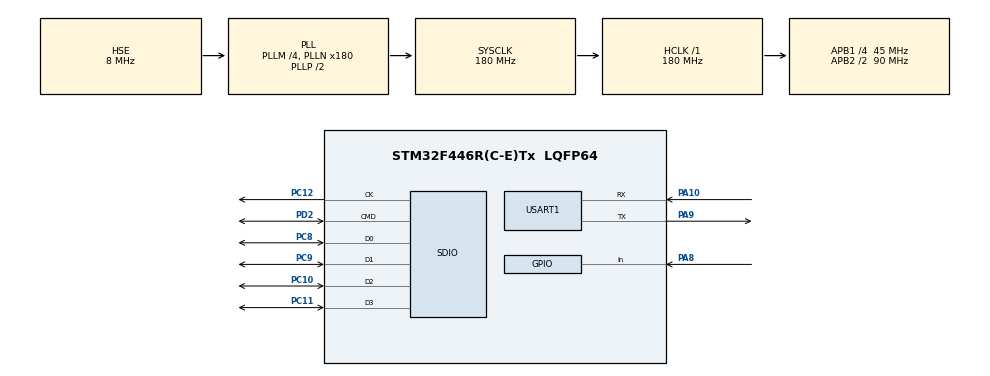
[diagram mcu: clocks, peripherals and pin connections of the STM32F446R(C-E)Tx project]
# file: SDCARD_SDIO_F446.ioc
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Dma.Request0=SDIO
Dma.SDIO.0.Direction=DMA_PERIPH_TO_MEMORY
Dma.SDIO.0.FIFOMode=DMA_FIFOMODE_ENABLE
Dma.SDIO.0.FIFOThreshold=DMA_FIFO_THRESHOLD_FULL
Dma.SDIO.0.Instance=DMA2_Stream3
Dma.SDIO.0.MemBurst=DMA_MBURST_INC4
Dma.SDIO.0.MemDataAlignment=DMA_MDATAALIGN_WORD
Dma.SDIO.0.MemInc=DMA_MINC_ENABLE
Dma.SDIO.0.Mode=DMA_PFCTRL
Dma.SDIO.0.PeriphBurst=DMA_PBURST_INC4
Dma.SDIO.0.PeriphDataAlignment=DMA_PDATAALIGN_WORD
Dma.SDIO.0.PeriphInc=DMA_PINC_DISABLE
Dma.SDIO.0.Priority=DMA_PRIORITY_LOW
FATFS.BSP.number=1
FATFS.USE_DMA_CODE_SD=1
FATFS._USE_LFN=3
FATFS0.BSP.STBoard=false
FATFS0.BSP.api=Unknown
FATFS0.BSP.instance=PA8
FATFS0.BSP.ip=GPIO
FATFS0.BSP.mode=Input
FATFS0.BSP.name=Detect_SDIO
FATFS0.BSP.solution=PA8
Mcu.Family=STM32F4
Mcu.Name=STM32F446R(C-E)Tx
Mcu.Package=LQFP64
NVIC.DMA2_Stream3_IRQn=true\:0\:0\:false\:false\:true\:false\:true\:true
NVIC.PriorityGroup=NVIC_PRIORITYGROUP_4
NVIC.SDIO_IRQn=true\:0\:0\:false\:false\:true\:true\:true\:true
PA10.Mode=Asynchronous
PA10.Signal=USART1_RX
PA13.Mode=Serial_Wire
PA13.Signal=SYS_JTMS-SWDIO
PA14.Mode=Serial_Wire
PA14.Signal=SYS_JTCK-SWCLK
PA8.Signal=GPIO_Input
PA9.Mode=Asynchronous
PA9.Signal=USART1_TX
PC10.Mode=SD_4_bits_Wide_bus
PC10.Signal=SDIO_D2
PC11.Mode=SD_4_bits_Wide_bus
PC11.Signal=SDIO_D3
PC12.Mode=SD_4_bits_Wide_bus
PC12.Signal=SDIO_CK
PC8.Mode=SD_4_bits_Wide_bus
PC8.Signal=SDIO_D0
PC9.Mode=SD_4_bits_Wide_bus
PC9.Signal=SDIO_D1
PD2.Mode=SD_4_bits_Wide_bus
PD2.Signal=SDIO_CMD
PH0-OSC_IN.Mode=HSE-External-Oscillator
PH0-OSC_IN.Signal=RCC_OSC_IN
PH1-OSC_OUT.Mode=HSE-External-Oscillator
PH1-OSC_OUT.Signal=RCC_OSC_OUT
ProjectManager.HeapSize=0x200
ProjectManager.StackSize=0x400
ProjectManager.TargetToolchain=STM32CubeIDE
RCC.AHBFreq_Value=180000000
RCC.APB1CLKDivider=RCC_HCLK_DIV4
RCC.APB1Freq_Value=45000000
RCC.APB1TimFreq_Value=90000000
RCC.APB2CLKDivider=RCC_HCLK_DIV2
RCC.APB2Freq_Value=90000000
RCC.APB2TimFreq_Value=180000000
RCC.CortexFreq_Value=180000000
RCC.HCLKFreq_Value=180000000
RCC.HSE_VALUE=8000000
RCC.PLLM=4
RCC.PLLN=180
RCC.PLLQ=10
RCC.PLLSourceVirtual=RCC_PLLSOURCE_HSE
RCC.SYSCLKFreq_VALUE=180000000
RCC.SYSCLKSource=RCC_SYSCLKSOURCE_PLLCLK
RCC.USBFreq_Value=36000000
RCC.VCOOutputFreq_Value=360000000
SDIO.ClockDiv=0
SDIO.HardwareFlowControl=SDIO_HARDWARE_FLOW_CONTROL_ENABLE
USART1.VirtualMode=VM_ASYNC
VP_FATFS_VS_SDIO.Mode=SDIO
board=custom

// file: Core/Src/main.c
/* USER CODE BEGIN Header */
/**
  ******************************************************************************
  * @file           : main.c
  * @brief          : Main program body
  ******************************************************************************
  * @attention
  *
  * Copyright (c) 2025 STMicroelectronics.
  * All rights reserved.
  *
  * This software is licensed under terms that can be found in the LICENSE file
  * in the root directory of this software component.
  * If no LICENSE file comes with this software, it is provided AS-IS.
  *
  ******************************************************************************
  */
/* USER CODE END Header */
#include "main.h"
#include "fatfs.h"

/* USER CODE BEGIN Includes */
#include "sd_functions.h"
#include "stdio.h"
#include "sd_benchmark.h"
/* USER CODE END Includes */

SD_HandleTypeDef hsd;
DMA_HandleTypeDef hdma_sdio;

UART_HandleTypeDef huart1;

void SystemClock_Config(void);
static void MX_GPIO_Init(void);
static void MX_DMA_Init(void);
static void MX_SDIO_SD_Init(void);
static void MX_USART1_UART_Init(void);

/* USER CODE BEGIN 0 */
int _write(int fd, unsigned char *buf, int len) {
  if (fd == 1 || fd == 2) {                     // stdout or stderr ?
    HAL_UART_Transmit(&huart1, buf, len, 999);  // Print to the UART
  }
  return len;
}

uint8_t bufr[100];
UINT br;

/* USER CODE END 0 */

int main(void)
{

  /* MCU Configuration--------------------------------------------------------*/

  /* Reset of all peripherals, Initializes the Flash interface and the Systick. */
  HAL_Init();

  /* Configure the system clock */
  SystemClock_Config();

  /* Initialize all configured peripherals */
  MX_GPIO_Init();
  MX_DMA_Init();
  MX_SDIO_SD_Init();
  MX_FATFS_Init();
  MX_USART1_UART_Init();
  /* USER CODE BEGIN 2 */

//  sd_mount();
//  sd_list_files();
//  sd_unmount();

//  sd_mount();
//  sd_read_file("F1/F1F2/FILE5.TXT", bufr, 100, &br);
//  printf("DATA: %s\n\n", bufr);
//  sd_unmount();

//  sd_mount();
//  sd_write_file("FILE8.TXT", "This is File 8 and it is in the root of the SD Card\n");
//  sd_read_file("FILE8.txt", bufr, 100, &br);
//  printf("DATA: %s\n\n", bufr);
//  sd_unmount();

//  sd_mount();
//  sd_append_file("FILE8.TXT", "THis is appended text to file8\n");
//  sd_read_file("FILE8.txt", bufr, 100, &br);
//  printf("DATA: %s\n\n", bufr);
//  sd_unmount();

//#define max_records 20
//  CsvRecord myrecords[max_records];
//  int record_count = 0;
//  sd_mount();
//  sd_read_csv("F1/F1F2/FILE4.CSV", myrecords, max_records, &record_count);
//  sd_unmount();

  sd_benchmark();

  /* USER CODE END 2 */

  /* Infinite loop */
  while (1)
  {

  }
}

void SystemClock_Config(void)
{
  RCC_OscInitTypeDef RCC_OscInitStruct = {0};
  RCC_ClkInitTypeDef RCC_ClkInitStruct = {0};

  /** Configure the main internal regulator output voltage
  */
  __HAL_RCC_PWR_CLK_ENABLE();
  __HAL_PWR_VOLTAGESCALING_CONFIG(PWR_REGULATOR_VOLTAGE_SCALE1);

  /** Initializes the RCC Oscillators according to the specified parameters
  * in the RCC_OscInitTypeDef structure.
  */
  RCC_OscInitStruct.OscillatorType = RCC_OSCILLATORTYPE_HSE;
  RCC_OscInitStruct.HSEState = RCC_HSE_ON;
  RCC_OscInitStruct.PLL.PLLState = RCC_PLL_ON;
  RCC_OscInitStruct.PLL.PLLSource = RCC_PLLSOURCE_HSE;
  RCC_OscInitStruct.PLL.PLLM = 4;
  RCC_OscInitStruct.PLL.PLLN = 180;
  RCC_OscInitStruct.PLL.PLLP = RCC_PLLP_DIV2;
  RCC_OscInitStruct.PLL.PLLQ = 10;
  RCC_OscInitStruct.PLL.PLLR = 2;
  if (HAL_RCC_OscConfig(&RCC_OscInitStruct) != HAL_OK)
  {
    Error_Handler();
  }

  /** Activate the Over-Drive mode
  */
  if (HAL_PWREx_EnableOverDrive() != HAL_OK)
  {
    Error_Handler();
  }

  /** Initializes the CPU, AHB and APB buses clocks
  */
  RCC_ClkInitStruct.ClockType = RCC_CLOCKTYPE_HCLK|RCC_CLOCKTYPE_SYSCLK
                              |RCC_CLOCKTYPE_PCLK1|RCC_CLOCKTYPE_PCLK2;
  RCC_ClkInitStruct.SYSCLKSource = RCC_SYSCLKSOURCE_PLLCLK;
  RCC_ClkInitStruct.AHBCLKDivider = RCC_SYSCLK_DIV1;
  RCC_ClkInitStruct.APB1CLKDivider = RCC_HCLK_DIV4;
  RCC_ClkInitStruct.APB2CLKDivider = RCC_HCLK_DIV2;

  if (HAL_RCC_ClockConfig(&RCC_ClkInitStruct, FLASH_LATENCY_5) != HAL_OK)
  {
    Error_Handler();
  }
}

static void MX_SDIO_SD_Init(void)
{
  hsd.Instance = SDIO;
  hsd.Init.ClockEdge = SDIO_CLOCK_EDGE_RISING;
  hsd.Init.ClockBypass = SDIO_CLOCK_BYPASS_DISABLE;
  hsd.Init.ClockPowerSave = SDIO_CLOCK_POWER_SAVE_DISABLE;
  hsd.Init.BusWide = SDIO_BUS_WIDE_4B;
  hsd.Init.HardwareFlowControl = SDIO_HARDWARE_FLOW_CONTROL_ENABLE;
  hsd.Init.ClockDiv = 0;
  /* USER CODE BEGIN SDIO_Init 2 */
  hsd.Init.BusWide = SDIO_BUS_WIDE_1B;  // add this
  /* USER CODE END SDIO_Init 2 */

}

static void MX_USART1_UART_Init(void)
{

  huart1.Instance = USART1;
  huart1.Init.BaudRate = 115200;
  huart1.Init.WordLength = UART_WORDLENGTH_8B;
  huart1.Init.StopBits = UART_STOPBITS_1;
  huart1.Init.Parity = UART_PARITY_NONE;
  huart1.Init.Mode = UART_MODE_TX_RX;
  huart1.Init.HwFlowCtl = UART_HWCONTROL_NONE;
  huart1.Init.OverSampling = UART_OVERSAMPLING_16;
  if (HAL_UART_Init(&huart1) != HAL_OK)
  {
    Error_Handler();
  }

}

static void MX_DMA_Init(void)
{

  /* DMA controller clock enable */
  __HAL_RCC_DMA2_CLK_ENABLE();

  /* DMA interrupt init */
  /* DMA2_Stream3_IRQn interrupt configuration */
  HAL_NVIC_SetPriority(DMA2_Stream3_IRQn, 0, 0);
  HAL_NVIC_EnableIRQ(DMA2_Stream3_IRQn);

}

static void MX_GPIO_Init(void)
{
  GPIO_InitTypeDef GPIO_InitStruct = {0};

  /* GPIO Ports Clock Enable */
  __HAL_RCC_GPIOH_CLK_ENABLE();
  __HAL_RCC_GPIOC_CLK_ENABLE();
  __HAL_RCC_GPIOA_CLK_ENABLE();
  __HAL_RCC_GPIOD_CLK_ENABLE();

  /*Configure GPIO pin : PA8 */
  GPIO_InitStruct.Pin = GPIO_PIN_8;
  GPIO_InitStruct.Mode = GPIO_MODE_INPUT;
  GPIO_InitStruct.Pull = GPIO_NOPULL;
  HAL_GPIO_Init(GPIOA, &GPIO_InitStruct);

}

void Error_Handler(void)
{
  __disable_irq();
  while (1)
  {
  }
}
